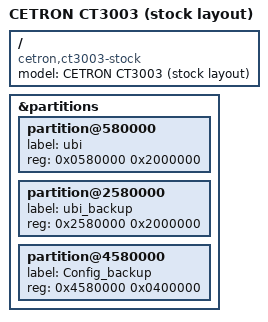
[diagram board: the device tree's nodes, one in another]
// SPDX-License-Identifier: GPL-2.0-or-later OR MIT

/dts-v1/;
#include "mt7981b-cetron-ct3003.dtsi"

/ {
	model = "CETRON CT3003 (stock layout)";
	compatible = "cetron,ct3003-stock", "mediatek,mt7981";
};

&partitions {
	partition@580000 {
		label = "ubi";
		reg = <0x0580000 0x2000000>;
	};

	partition@2580000 {
		label = "ubi_backup";
		reg = <0x2580000 0x2000000>;
	};

	partition@4580000 {
		label = "Config_backup";
		reg = <0x4580000 0x0400000>;
	};
};
